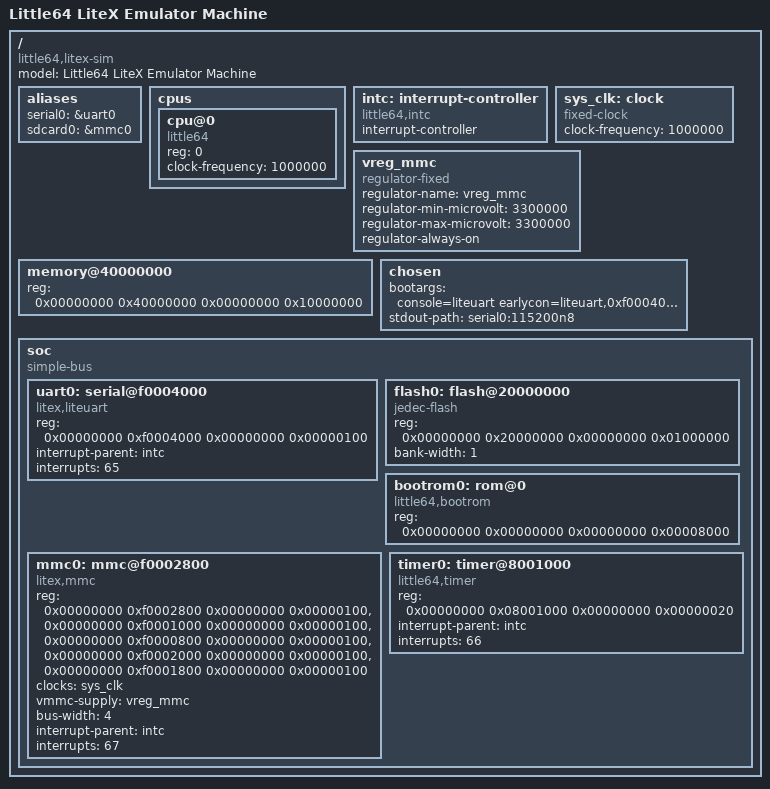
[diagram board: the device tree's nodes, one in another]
/dts-v1/;

/ {
    #address-cells = <2>;
    #size-cells = <2>;
    compatible = "little64,litex-sim", "little64,bootrom";
    model = "Little64 LiteX Emulator Machine";

    aliases {
        serial0 = &uart0;
        sdcard0 = &mmc0;
    };

    cpus {
        #address-cells = <1>;
        #size-cells = <0>;

        cpu@0 {
            compatible = "little64";
            device_type = "cpu";
            reg = <0>;
            clock-frequency = <1000000>;
        };
    };

    intc: interrupt-controller {
        compatible = "little64,intc";
        interrupt-controller;
        #interrupt-cells = <1>;
    };

    sys_clk: clock {
        compatible = "fixed-clock";
        #clock-cells = <0>;
        clock-frequency = <1000000>;
    };

    vreg_mmc: vreg_mmc {
        compatible = "regulator-fixed";
        regulator-name = "vreg_mmc";
        regulator-min-microvolt = <3300000>;
        regulator-max-microvolt = <3300000>;
        regulator-always-on;
    };

    memory@40000000 {
        device_type = "memory";
        reg = <0x00000000 0x40000000 0x00000000 0x10000000>;
    };

    chosen {
        bootargs = "console=liteuart earlycon=liteuart,0xf0004000 ignore_loglevel loglevel=8 root=/dev/mmcblk0p2 rootwait init=/init";
        stdout-path = "serial0:115200n8";
    };

    soc {
        compatible = "simple-bus";
        #address-cells = <2>;
        #size-cells = <2>;
        ranges;

        uart0: serial@f0004000 {
            compatible = "litex,liteuart";
            reg = <0x00000000 0xf0004000 0x00000000 0x00000100>;
            interrupt-parent = <&intc>;
            interrupts = <65>;
        };

        flash0: flash@20000000 {
            compatible = "jedec-flash";
            reg = <0x00000000 0x20000000 0x00000000 0x01000000>;
            bank-width = <1>;
        };

        bootrom0: rom@0 {
            compatible = "little64,bootrom";
            reg = <0x00000000 0x00000000 0x00000000 0x00008000>;
        };

        mmc0: mmc@f0002800 {
            compatible = "litex,mmc";
            reg = <0x00000000 0xf0002800 0x00000000 0x00000100>,
                  <0x00000000 0xf0001000 0x00000000 0x00000100>,
                  <0x00000000 0xf0000800 0x00000000 0x00000100>,
                  <0x00000000 0xf0002000 0x00000000 0x00000100>,
                  <0x00000000 0xf0001800 0x00000000 0x00000100>;
            reg-names = "phy", "core", "reader", "writer", "irq";
            clocks = <&sys_clk>;
            vmmc-supply = <&vreg_mmc>;
            bus-width = <4>;
            interrupt-parent = <&intc>;
            interrupts = <67>;
        };

        timer0: timer@8001000 {
            compatible = "little64,timer";
            reg = <0x00000000 0x08001000 0x00000000 0x00000020>;
            interrupt-parent = <&intc>;
            interrupts = <66>;
        };
    };
};
